# ENUMS register map
File version: 1.0
Registers are 32-bit, read-write, no defined reset value unless marked. A register's access mark holds for its fields unless they carry their own. Offsets are from the block's base; lines under a group give offsets from that group; [hi:lo] are bit positions; {n}, {i} and the like mark numbered series; 'fields as' and 'values as' point back to an identical list; <NAME> marks a mode.

## Memory map
0x40000000 ENUMS — The enums.
0x40001000 ENUMS2 — Shares the type of ENUMS: its sets are not written.
0x40002000 OTHER — A type of its own, whose sets derive from the ones of ENUMS.

## ENUMS — The enums.
Base 0x40000000
Same registers: ENUMS2 0x40001000
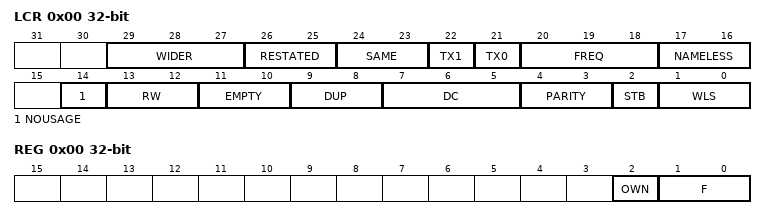
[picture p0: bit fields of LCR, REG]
0x00 LCR — A register with a field per case.
  [29:27] WIDER — Derived, and adds a value: a set of its own, an enum of its own.
    4=NINE
  [26:25] RESTATED — Derived, and states a value the base has, as it has it: still the same enum.
    1=SIX
  [24:23] SAME — Derived from the set WLS_VALUES of a sibling field: the same enum.
    0=FIVE (Five bits.); 1=SIX (Six bits.); 2=SEVEN; 3=EIGHT
  [n+21] TX{n} (n=0..1) — A field with dim and enumerated values: one enum, shared.
    0=OFF; 1=ON
  [20:18] FREQ — Names with a leading digit, a digit alone, and nothing for an identifier.
    0=0; 1=1MHZ; 2=-; 4=OK
  [17:16] NAMELESS — A value without a name is no variant, and nothing is warned.
    0=A; 1=B
  [14] NOUSAGE — Two sets without a usage: also no declaration, and a bool for one bit.
    0=A; 1=B
  [13:12] RW — Two sets, for reads and for writes: no declaration.
    on read: 0=IDLE; 1=BUSY | on write: 1=GO
  [11:10] EMPTY — No variant is left: the field is an integer.
    other=OTHERS; 0b1x=WIDE
  [9:8] DUP — A value another variant has is left out.
    0=A; 1=B; 1=C
  [7:5] DC — A value with don't-care bits is left out.
    0=A; 1=B; 0b1x0=MANY
  [4:3] PARITY — An isDefault value is no variant.
    0=NONE; 1=ODD; 3=EVEN; other=RESERVED (Every other value.)
  [2] STB — One bit with an enum: an enum, not a bool.
    0=ONE; 1=TWO
  [1:0] WLS — The word length.
    0=FIVE (Five bits.); 1=SIX (Six bits.); 2=SEVEN; 3=EIGHT
0x100 CL group — A cluster: its register names the enum of the peripheral type, through super.
  0x00 REG
    [2] OWN
      0=NO; 1=YES
    [1:0] F
      0=FIVE (Five bits.); 1=SIX (Six bits.); 2=SEVEN; 3=EIGHT

## OTHER — A type of its own, whose sets derive from the ones of ENUMS.
Base 0x40002000
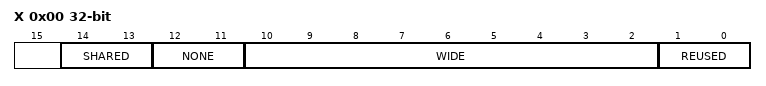
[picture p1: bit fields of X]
0x00 X
  [14:13] SHARED — A set of a peripheral that shares the type of ENUMS: not in the model, so an enum of its own.
    0=FIVE (Five bits.); 1=SIX (Six bits.); 2=SEVEN; 3=EIGHT
  [12:11] NONE — The set was not written as an enum: an integer.
    other=OTHERS; 0b1x=WIDE
  [10:2] WIDE — The same set on another integer type: an enum of its own.
    0=FIVE (Five bits.); 1=SIX (Six bits.); 2=SEVEN; 3=EIGHT
  [1:0] REUSED — The enum of ENUMS, through its module.
    0=FIVE (Five bits.); 1=SIX (Six bits.); 2=SEVEN; 3=EIGHT
